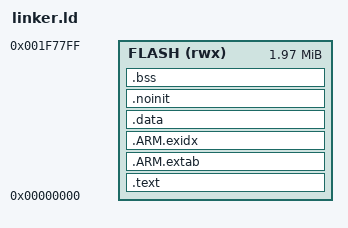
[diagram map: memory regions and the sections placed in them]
/* Linker script for aic8800 */

/* Linker script to configure memory regions. */
MEMORY
{
    FLASH (rwx)     : ORIGIN = 0x00000000, LENGTH = 2014K
}

/* Linker script to place sections and symbol values. Should be used together
 * with other linker script that defines memory regions FLASH and RAM.
 * It references following symbols, which must be defined in code:
 *   Reset_Handler : Entry of reset handler
 *
 * It defines following symbols, which code can use without definition:
 *   __exidx_start
 *   __exidx_end
 *   __etext
 *   __data_start__
 *   __preinit_array_start
 *   __preinit_array_end
 *   __init_array_start
 *   __init_array_end
 *   __fini_array_start
 *   __fini_array_end
 *   __data_end__
 *   __bss_start__
 *   __bss_end__
 *   __end__
 *   end
 *   __HeapLimit
 *   __StackLimit
 *   __StackTop
 *   __stack
 */

SECTIONS
{
    .text :
    {
        *(.text*)

        KEEP(*(.init))
        KEEP(*(.fini))

        /* .ctors */
        *crtbegin.o(.ctors)
        *crtbegin?.o(.ctors)
        *(EXCLUDE_FILE(*crtend?.o *crtend.o) .ctors)
        *(SORT(.ctors.*))
        *(.ctors)

        /* .dtors */
        *crtbegin.o(.dtors)
        *crtbegin?.o(.dtors)
        *(EXCLUDE_FILE(*crtend?.o *crtend.o) .dtors)
        *(SORT(.dtors.*))
        *(.dtors)

        *(.rodata*)

        KEEP(*(.eh_frame*))
    } > FLASH

    .ARM.extab :
    {
        *(.ARM.extab* .gnu.linkonce.armextab.*)
    } > FLASH

    .ARM.exidx :
    {
       __exidx_start = .;
        *(.ARM.exidx* .gnu.linkonce.armexidx.*)
       __exidx_end = .;
    } > FLASH

    .data :
    {
        __data_start__ = .;
        *(vtable)
        *(.data*)

        . = ALIGN(4);
        /* preinit data */
        PROVIDE_HIDDEN (__preinit_array_start = .);
        KEEP(*(.preinit_array))
        PROVIDE_HIDDEN (__preinit_array_end = .);

        . = ALIGN(4);
        /* init data */
        PROVIDE_HIDDEN (__init_array_start = .);
        KEEP(*(SORT_BY_INIT_PRIORITY(.init_array*)))
        PROVIDE_HIDDEN (__init_array_end = .);

        . = ALIGN(4);
        /* finit data */
        PROVIDE_HIDDEN (__fini_array_start = .);
        KEEP(*(SORT_BY_INIT_PRIORITY(.fini_array*)))
        PROVIDE_HIDDEN (__fini_array_end = .);

        . = ALIGN(4);
        /* All data end */
        __data_end__ = .;

    } > FLASH

    .noinit (NOLOAD):
    {
        *(.bss.noinit* .noinit*)
    } > FLASH

    .bss (NOLOAD):
    {
        __bss_start__ = .;
        *(.bss*)
        *(COMMON)
        __bss_end__ = .;
    } > FLASH
}
